# R9A02G021 register map
Vendor: Renesas Electronics Corporation; Series: RISC-V; File version: 1.10.00 + 202304131714_CPU
CPU: other r0p0, little endian, no MPU, no FPU, VTOR, 4 interrupt priority bits, 32 interrupts
Registers are 8-bit, read-write, reset 0x0 unless marked. A register's access mark holds for its fields unless they carry their own. Offsets are from the block's base; [hi:lo] are bit positions; {n}, {i} and the like mark numbered series; <NAME> marks a mode.

## KINT — Key Interrupt Function
Base 0x40080000
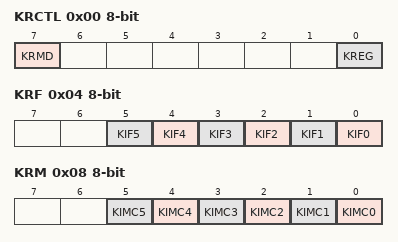
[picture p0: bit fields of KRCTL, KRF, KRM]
0x00 KRCTL — Key Return Control Register
  [7] KRMD — Usage of Key Interrupt Flags (KRF.KIF0 to KRF.KIF5)
    0=Do not use key interrupt flags; 1=Use key interrupt flags
  [0] KREG — Detection Edge Selection (KR00 to KR05 pins)
    0=Falling edge; 1=Rising edge
0x04 KRF — Key Return Flag Register
  [all] fields
    0=No interrupt detected; 1=Interrupt detected
  [n] KIF{n} (n=0..5) — Key Interrupt Flag n
0x08 KRM — Key Return Mode Register
  [all] fields
    0=Do not detect key interrupt signals; 1=Detect key interrupt signals
  [n] KIMC{n} (n=0..5) — Key Interrupt Mode Control n

## DOC — Data Operation Circuit
Base 0x40085F00
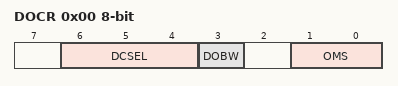
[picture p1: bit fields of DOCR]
0x00 DOCR — DOC Control Register
  [6:4] DCSEL — Detection Condition Select
    0=Mismatch (DODSR0 ≠ DODIR); 1=Match (DODSR0 = DODIR); 2=Lower (DODSR0 > DODIR); 3=Upper (DODSR0 < DODIR); 4=Inside window (DODSR0 < DODIR < DODSR1); 5=Outside window (DODIR < DODSR0, DODSR1 < DODIR); other=Others (Setting prohibited)
  [3] DOBW — Data Operation Bit Width Select
    0=16-bit; 1=32-bit
  [1:0] OMS — Operating Mode Select
    0=Data comparison mode; 1=Data addition mode; 2=Data subtraction mode; 3=Setting prohibited
0x04 DOSR ro — DOC Flag Status Register
  [0] DOPCF — Data Operation Circuit Flag
0x08 DOSCR wo — DOC Flag Status Clear Register
  [0] DOPCFCL — DOPCF Clear
    0=Maintains the DOPCF flag state; 1=Clears the DOPCF flag
0x0C DODIR 32-bit — DOC Data Input Register
0x10 DODSR0 32-bit — DOC Data Setting Register 0
0x14 DODSR1 32-bit — DOC Data Setting Register 1

## PORGA — Product Organize Register
Base 0x40091000
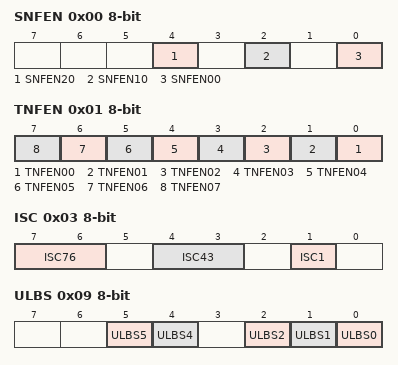
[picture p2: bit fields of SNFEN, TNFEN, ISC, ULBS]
0x00 SNFEN — SAU Noise Filter Enable Register
  [all] fields
    0=Noise filter OFF; 1=Noise filter ON
  [4] SNFEN20 — Use of noise filter of RxD2 pin
  [2] SNFEN10 — Use of noise filter of RxD1 pin
  [0] SNFEN00 — Use of noise filter of RxD0 pin
0x01 TNFEN — TAU Noise Filter Enable Register
  [all] fields
    0=Turns the noise filter off; 1=Turns the noise filter on
  [n] TNFEN{n:02} (n=0..7) — Enabling or disabling use of the noise filter for the TI{n:02} pin
0x03 ISC — Input Switch Control Register
  [7:6] ISC76 — Switch of the serial clock input source of SPI01
    0=Input signal of the SCK01 pin (normal operation); 2=TO01 output signal; other=Others (Setting prohibited)
  [4:3] ISC43 — Switch of the serial clock input source of SPI00
    0=Input signal of the SCK00 pin (normal operation); 2=TO01 output signal; other=Others (Setting prohibited)
  [1] ISC1 — Switching channel 7 input of timer array unit
    0=Uses the input signal of the TI07 pin as a timer input (normal operation); 1=Input signal of the RxD2 pin is used as timer input (detects the wakeup signal and measures the low width of the break field and the pulse width of the sync field)
0x04 TIS0 — Timer Input Select Register 0
  [2:0] TIS — Selection of timer input used with channel 5
    0=Input signal of timer input pin (TI05); 3=Middle-speed on-chip oscillator (MOCO); 4=Low-speed on-chip oscillator (LOCO); 5=Sub-clock oscillator (SOSC); other=Others (Setting prohibited)
0x09 ULBS — UART Loopback Select Register
  [5] ULBS5 — Selection of the UARTA1 loopback function
    0=Inputs the states of the RxDA1 pin of serial interface UARTA1 to the reception shift register; 1=Loops back output from the transmission shift register to the reception shift register
  [4] ULBS4 — Selection of the UARTA0 loopback function
    0=Inputs the states of the RxDA0 pin of serial interface UARTA0 to the reception shift register; 1=Loops back output from the transmission shift register to the reception shift register
  [2] ULBS2 — Selection of the UART2 loopback function
    0=Inputs the states of the RxD2 pin of serial array unit UART2 to the reception shift register; 1=Loops back output from the transmission shift register to the reception shift register
  [1] ULBS1 — Selection of the UART1 loopback function
    0=Inputs the states of the RxD1 pin of serial array unit UART1 to the reception shift register; 1=Loops back output from the transmission shift register to the reception shift register
  [0] ULBS0 — Selection of the UART0 loopback function
    0=Inputs the states of the RxD0 pin of serial array unit UART0 to the reception shift register; 1=Loops back output from the transmission shift register to the reception shift register
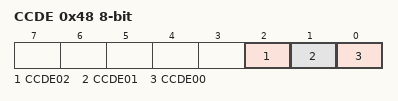
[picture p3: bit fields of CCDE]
0x48 CCDE — Output Current Control Enable Register
  [all] fields
    0=Disable (digital I/O); 1=Enable (current control function)
  [2] CCDE02 — CCDE02 (P303) output control function
  [1] CCDE01 — CCDE01 (P302) output control function
  [0] CCDE00 — CCDE00 (P100) output control function
0x81 CCTRM — Output Current Control Trimming Register
  [3:0] IADJ — Output current control trimming
